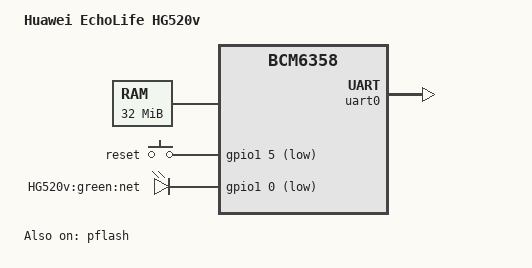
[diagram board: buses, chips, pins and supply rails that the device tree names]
/dts-v1/;

#include "bcm6358.dtsi"

/ {
	compatible = "huawei,hg520v", "brcm,bcm6358";
	model = "Huawei EchoLife HG520v";

	chosen {
		bootargs = "console=ttyS0,115200 earlycon";
	};

	aliases {
		led-boot = &inet_green;
		led-failsafe = &inet_green;
		led-running = &inet_green;
	};

	memory@0 {
		device_type = "memory";
		reg = <0x00000000 0x02000000>;
	};

	gpio-keys-polled {
		compatible = "gpio-keys-polled";
		#address-cells = <1>;
		#size-cells = <0>;
		poll-interval = <20>;
		debounce-interval = <60>;

		reset {
			label = "reset";
			gpios = <&gpio1 5 GPIO_ACTIVE_LOW>;
			linux,code = <KEY_RESTART>;
		};
	};

	gpio-leds {
		compatible = "gpio-leds";

		inet_green: inet_green {
			label = "HG520v:green:net";
			gpios = <&gpio1 0 GPIO_ACTIVE_LOW>;
		};
	};
};

&pflash {
	status = "ok";

	partitions {
		compatible = "fixed-partitions";
		#address-cells = <1>;
		#size-cells = <1>;

		cfe@0 {
			label = "CFE";
			reg = <0x000000 0x010000>;
			read-only;
		};
		firmware@10000 {
			label = "firmware";
			reg = <0x010000 0x3e0000>;
		};
		nvram@3f0000 {
			label = "nvram";
			reg = <0x3f0000 0x010000>;
			read-only;
		};
	};
};

&uart0 {
	status = "ok";
};
